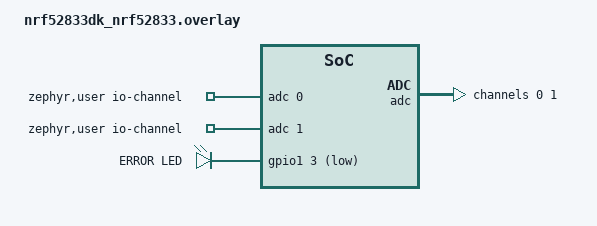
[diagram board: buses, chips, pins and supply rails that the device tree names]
// To get started, press Ctrl+Space (or Option+Esc) to bring up the completion menu and view the available nodes.

// You can also use the buttons in the sidebar to perform actions on nodes.
// Actions currently available include:

// * Enabling / disabling the node
// * Adding the bus to a bus
// * Removing the node
// * Connecting ADC channels

// For more help, browse the DeviceTree documentation at https://docs.zephyrproject.org/latest/guides/dts/index.html
// You can also visit the nRF DeviceTree extension documentation at https://nrfconnect.github.io/vscode-nrf-connect/devicetree/nrfdevicetree.html
/ {
	zephyr,user {
		io-channels = <&adc 0>, <&adc 1>;
	};
    aliases{
        reslow = &reslow;
        reshigh = &reshigh;
        heartbeat = &led0;
        buzzer = &led1;
        ivdrip = &led2;
        alarm = &led3;
        error = &led4;
        button0=&button0;
        button1=&button1;
        button2=&button2;
        button3=&button3;
    };
    leds{
        compatible = "gpio-leds";
        led4: led_4{
            gpios = < &gpio1 3 GPIO_ACTIVE_LOW>;
            label = "ERROR LED";
        };
    };
};
&adc {
	#address-cells = <1>;
	#size-cells = <0>;

	reslow: channel@0 {
		reg = <0>;
		zephyr,gain = "ADC_GAIN_1_5";
		zephyr,reference = "ADC_REF_INTERNAL";
		zephyr,acquisition-time = <ADC_ACQ_TIME_DEFAULT>;
		zephyr,input-positive = <NRF_SAADC_AIN0>; // P0.02
		zephyr,resolution = <8>;
	};

	reshigh: channel@1 {
		reg = <1>;
		zephyr,gain = "ADC_GAIN_1_5";
		zephyr,reference = "ADC_REF_VDD_1";
		zephyr,acquisition-time = <ADC_ACQ_TIME_DEFAULT>;
		zephyr,input-positive = <NRF_SAADC_AIN1>; // P0.03
		zephyr,resolution = <12>;
	};

	status = "okay";
};
